# bao1x_peri register map
Vendor: baochip
Registers are 32-bit, read-write, reset 0x0 unless marked. A register's access mark holds for its fields unless they carry their own. Offsets are from the block's base; [hi:lo] are bit positions; {n}, {i} and the like mark numbered series; <NAME> marks a mode.

## UDMA_FILTER
Base 0x50110000
0x00 REG_TX_CH0_ADD — See `udma_filter_reg_if.sv <https://github.com/baochip/baochip-1x/blob/main/rtl/ ips/udma/udma_filter/rtl/udma_filter_reg_if.sv>`__
  [14:0] r_filter_tx_start_addr_0
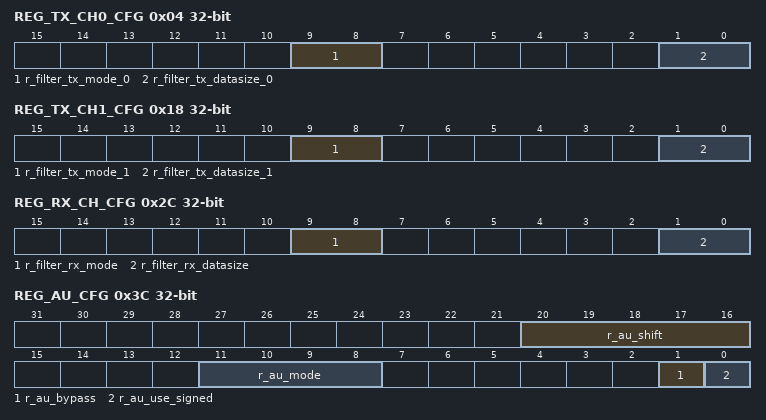
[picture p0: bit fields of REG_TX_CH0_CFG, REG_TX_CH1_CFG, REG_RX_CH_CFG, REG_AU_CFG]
0x04 REG_TX_CH0_CFG — See `udma_filter_reg_if.sv <https://github.com/baochip/baochip-1x/blob/main/rtl/ ips/udma/udma_filter/rtl/udma_filter_reg_if.sv>`__
  [9:8] r_filter_tx_mode_0, [1:0] r_filter_tx_datasize_0
{0x8+4i} REG_TX_CH0_LEN{i} (i=0..2) — See `udma_filter_reg_if.sv <https://github.com/baochip/baochip-1x/blob/main/rtl/ ips/udma/udma_filter/rtl/udma_filter_reg_if.sv>`__
  [14:0] r_filter_tx_len{i}_0
0x14 REG_TX_CH1_ADD — See `udma_filter_reg_if.sv <https://github.com/baochip/baochip-1x/blob/main/rtl/ ips/udma/udma_filter/rtl/udma_filter_reg_if.sv>`__
  [14:0] r_filter_tx_start_addr_1
0x18 REG_TX_CH1_CFG — See `udma_filter_reg_if.sv <https://github.com/baochip/baochip-1x/blob/main/rtl/ ips/udma/udma_filter/rtl/udma_filter_reg_if.sv>`__
  [9:8] r_filter_tx_mode_1, [1:0] r_filter_tx_datasize_1
{0x1C+4i} REG_TX_CH1_LEN{i} (i=0..2) — See `udma_filter_reg_if.sv <https://github.com/baochip/baochip-1x/blob/main/rtl/ ips/udma/udma_filter/rtl/udma_filter_reg_if.sv>`__
  [14:0] r_filter_tx_len{i}_1
0x28 REG_RX_CH_ADD — See `udma_filter_reg_if.sv <https://github.com/baochip/baochip-1x/blob/main/rtl/ ips/udma/udma_filter/rtl/udma_filter_reg_if.sv>`__
  [14:0] r_filter_rx_start_addr
0x2C REG_RX_CH_CFG — See `udma_filter_reg_if.sv <https://github.com/baochip/baochip-1x/blob/main/rtl/ ips/udma/udma_filter/rtl/udma_filter_reg_if.sv>`__
  [9:8] r_filter_rx_mode, [1:0] r_filter_rx_datasize
{0x30+4i} REG_RX_CH_LEN{i} (i=0..2) — See `udma_filter_reg_if.sv <https://github.com/baochip/baochip-1x/blob/main/rtl/ ips/udma/udma_filter/rtl/udma_filter_reg_if.sv>`__
  [15:0] r_filter_rx_len{i}
0x3C REG_AU_CFG — See `udma_filter_reg_if.sv <https://github.com/baochip/baochip-1x/blob/main/rtl/ ips/udma/udma_filter/rtl/udma_filter_reg_if.sv>`__
  [20:16] r_au_shift, [11:8] r_au_mode, [1] r_au_bypass, [0] r_au_use_signed
0x40 REG_AU_REG0 — See `udma_filter_reg_if.sv <https://github.com/baochip/baochip-1x/blob/main/rtl/ ips/udma/udma_filter/rtl/udma_filter_reg_if.sv>`__
  [31:0] r_commit_au_reg0
0x44 REG_AU_REG1 — See `udma_filter_reg_if.sv <https://github.com/baochip/baochip-1x/blob/main/rtl/ ips/udma/udma_filter/rtl/udma_filter_reg_if.sv>`__
  [31:0] r_commit_au_reg1
0x48 REG_BINCU_TH — See `udma_filter_reg_if.sv <https://github.com/baochip/baochip-1x/blob/main/rtl/ ips/udma/udma_filter/rtl/udma_filter_reg_if.sv>`__
  [31:0] r_commit_bincu_threshold
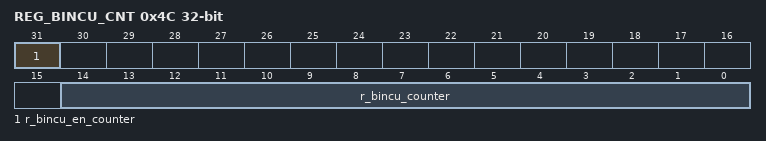
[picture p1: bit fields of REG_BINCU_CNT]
0x4C REG_BINCU_CNT — See `udma_filter_reg_if.sv <https://github.com/baochip/baochip-1x/blob/main/rtl/ ips/udma/udma_filter/rtl/udma_filter_reg_if.sv>`__
  [31] r_bincu_en_counter, [14:0] r_bincu_counter
0x50 REG_BINCU_SETUP — See `udma_filter_reg_if.sv <https://github.com/baochip/baochip-1x/blob/main/rtl/ ips/udma/udma_filter/rtl/udma_filter_reg_if.sv>`__
  [1:0] r_bincu_datasize
0x54 REG_BINCU_VAL — See `udma_filter_reg_if.sv <https://github.com/baochip/baochip-1x/blob/main/rtl/ ips/udma/udma_filter/rtl/udma_filter_reg_if.sv>`__
  [14:0] bincu_counter_i
0x58 REG_FILT — See `udma_filter_reg_if.sv <https://github.com/baochip/baochip-1x/blob/main/rtl/ ips/udma/udma_filter/rtl/udma_filter_reg_if.sv>`__
  [3:0] r_filter_mode
0x60 REG_STATUS — See `udma_filter_reg_if.sv <https://github.com/baochip/baochip-1x/blob/main/rtl/ ips/udma/udma_filter/rtl/udma_filter_reg_if.sv>`__
  [0] r_filter_done

## UDMA_SCIF
Base 0x50111000
0x00 REG_RX_SADDR — See `udma_scif_reg.sv <https://github.com/baochip/baochip-1x/blob/main/rtl/modul es/ifsub/rtl/udma_scif_reg.sv>`__
  [11:0] r_rx_startaddr
0x04 REG_RX_SIZE — See `udma_scif_reg.sv <https://github.com/baochip/baochip-1x/blob/main/rtl/modul es/ifsub/rtl/udma_scif_reg.sv>`__
  [15:0] r_rx_size
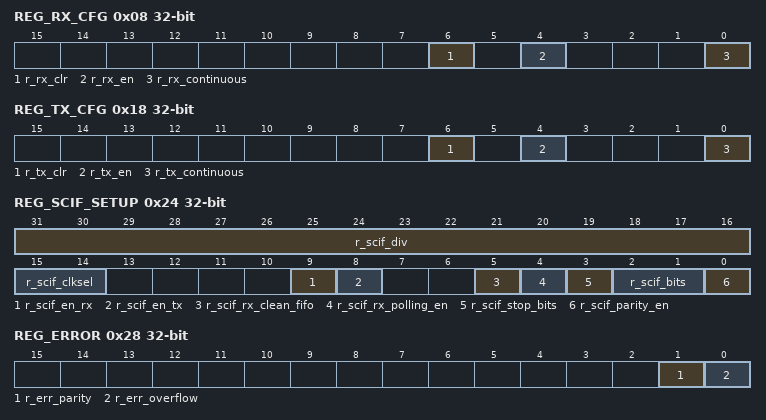
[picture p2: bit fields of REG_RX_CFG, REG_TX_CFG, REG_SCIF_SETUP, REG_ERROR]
0x08 REG_RX_CFG — See `udma_scif_reg.sv <https://github.com/baochip/baochip-1x/blob/main/rtl/modul es/ifsub/rtl/udma_scif_reg.sv>`__
  [6] r_rx_clr, [4] r_rx_en, [0] r_rx_continuous
0x10 REG_TX_SADDR — See `udma_scif_reg.sv <https://github.com/baochip/baochip-1x/blob/main/rtl/modul es/ifsub/rtl/udma_scif_reg.sv>`__
  [11:0] r_tx_startaddr
0x14 REG_TX_SIZE — See `udma_scif_reg.sv <https://github.com/baochip/baochip-1x/blob/main/rtl/modul es/ifsub/rtl/udma_scif_reg.sv>`__
  [15:0] r_tx_size
0x18 REG_TX_CFG — See `udma_scif_reg.sv <https://github.com/baochip/baochip-1x/blob/main/rtl/modul es/ifsub/rtl/udma_scif_reg.sv>`__
  [6] r_tx_clr, [4] r_tx_en, [0] r_tx_continuous
0x20 REG_STATUS — See `udma_scif_reg.sv <https://github.com/baochip/baochip-1x/blob/main/rtl/modul es/ifsub/rtl/udma_scif_reg.sv>`__
  [0] status_i
0x24 REG_SCIF_SETUP — See `udma_scif_reg.sv <https://github.com/baochip/baochip-1x/blob/main/rtl/modul es/ifsub/rtl/udma_scif_reg.sv>`__
  [31:16] r_scif_div, [15:14] r_scif_clksel, [9] r_scif_en_rx, [8] r_scif_en_tx, [5] r_scif_rx_clean_fifo, [4] r_scif_rx_polling_en, [3] r_scif_stop_bits, [2:1] r_scif_bits, [0] r_scif_parity_en
0x28 REG_ERROR — See `udma_scif_reg.sv <https://github.com/baochip/baochip-1x/blob/main/rtl/modul es/ifsub/rtl/udma_scif_reg.sv>`__
  [1] r_err_parity, [0] r_err_overflow
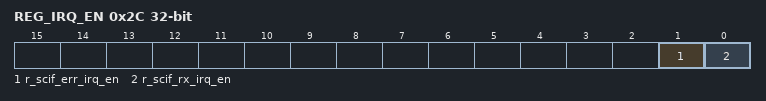
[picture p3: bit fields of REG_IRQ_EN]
0x2C REG_IRQ_EN — See `udma_scif_reg.sv <https://github.com/baochip/baochip-1x/blob/main/rtl/modul es/ifsub/rtl/udma_scif_reg.sv>`__
  [1] r_scif_err_irq_en, [0] r_scif_rx_irq_en
0x30 REG_VALID — See `udma_scif_reg.sv <https://github.com/baochip/baochip-1x/blob/main/rtl/modul es/ifsub/rtl/udma_scif_reg.sv>`__
  [0] r_scif_rx_data_valid
0x34 REG_DATA — See `udma_scif_reg.sv <https://github.com/baochip/baochip-1x/blob/main/rtl/modul es/ifsub/rtl/udma_scif_reg.sv>`__
  [7:0] r_scif_rx_data
0x38 REG_SCIF_ETU — See `udma_scif_reg.sv <https://github.com/baochip/baochip-1x/blob/main/rtl/modul es/ifsub/rtl/udma_scif_reg.sv>`__
  [15:0] r_scif_etu
